VERSION ""

NS_ :

BS_:

BU_: shit BMS

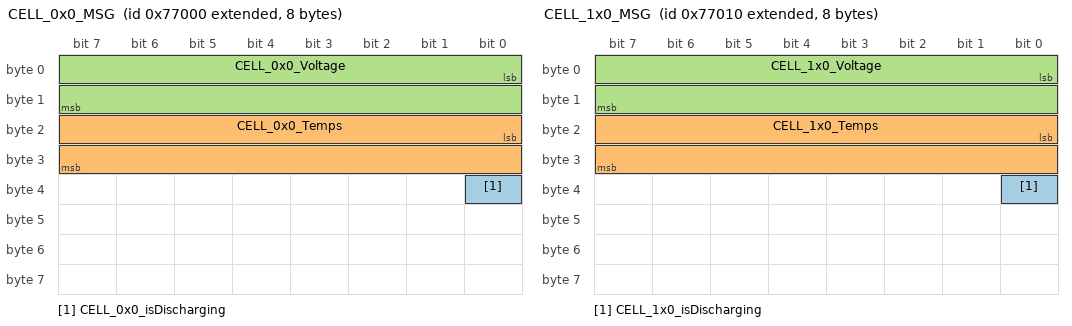
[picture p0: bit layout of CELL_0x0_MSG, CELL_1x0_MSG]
BO_ 2147971072 CELL_0x0_MSG: 8 BMS
 SG_ CELL_0x0_isDischarging : 32|1@1- (1,0) [0|0] "V" Vector__XXX
 SG_ CELL_0x0_Temps : 16|16@1- (1,0) [0|0] "V" Vector__XXX
 SG_ CELL_0x0_Voltage : 0|16@1- (1,0) [0|0] "V" Vector__XXX

BO_ 2147971088 CELL_1x0_MSG: 8 BMS
 SG_ CELL_1x0_isDischarging : 32|1@1- (1,0) [0|0] "V" Vector__XXX
 SG_ CELL_1x0_Temps : 16|16@1- (1,0) [0|0] "V" Vector__XXX
 SG_ CELL_1x0_Voltage : 0|16@1- (1,0) [0|0] "V" Vector__XXX

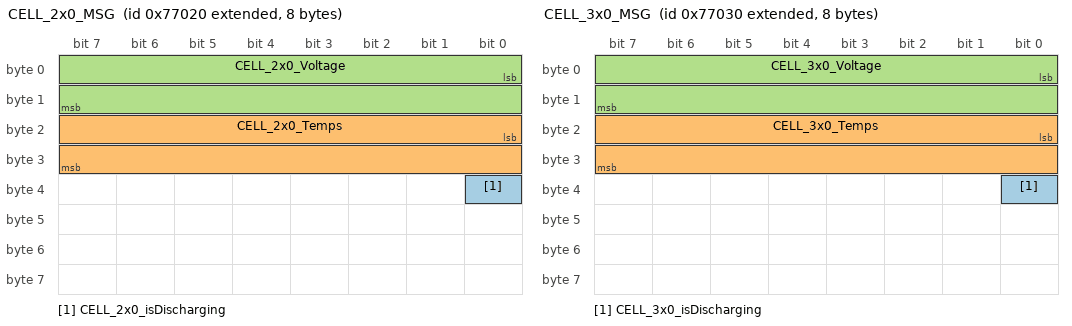
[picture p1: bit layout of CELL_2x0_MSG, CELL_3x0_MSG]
BO_ 2147971104 CELL_2x0_MSG: 8 BMS
 SG_ CELL_2x0_isDischarging : 32|1@1- (1,0) [0|0] "V" Vector__XXX
 SG_ CELL_2x0_Temps : 16|16@1- (1,0) [0|0] "V" Vector__XXX
 SG_ CELL_2x0_Voltage : 0|16@1- (1,0) [0|0] "V" Vector__XXX

BO_ 2147971120 CELL_3x0_MSG: 8 BMS
 SG_ CELL_3x0_isDischarging : 32|1@1- (1,0) [0|0] "V" Vector__XXX
 SG_ CELL_3x0_Temps : 16|16@1- (1,0) [0|0] "V" Vector__XXX
 SG_ CELL_3x0_Voltage : 0|16@1- (1,0) [0|0] "V" Vector__XXX

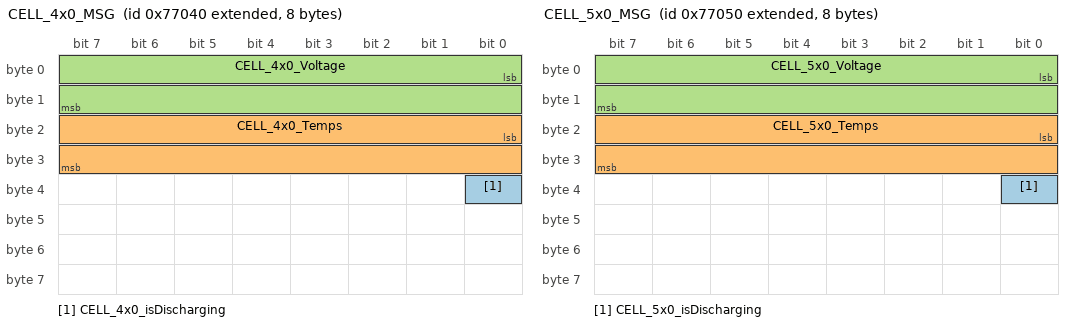
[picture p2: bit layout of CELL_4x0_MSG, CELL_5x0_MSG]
BO_ 2147971136 CELL_4x0_MSG: 8 BMS
 SG_ CELL_4x0_isDischarging : 32|1@1- (1,0) [0|0] "V" Vector__XXX
 SG_ CELL_4x0_Temps : 16|16@1- (1,0) [0|0] "V" Vector__XXX
 SG_ CELL_4x0_Voltage : 0|16@1- (1,0) [0|0] "V" Vector__XXX

BO_ 2147971152 CELL_5x0_MSG: 8 BMS
 SG_ CELL_5x0_isDischarging : 32|1@1- (1,0) [0|0] "V" Vector__XXX
 SG_ CELL_5x0_Temps : 16|16@1- (1,0) [0|0] "V" Vector__XXX
 SG_ CELL_5x0_Voltage : 0|16@1- (1,0) [0|0] "V" Vector__XXX

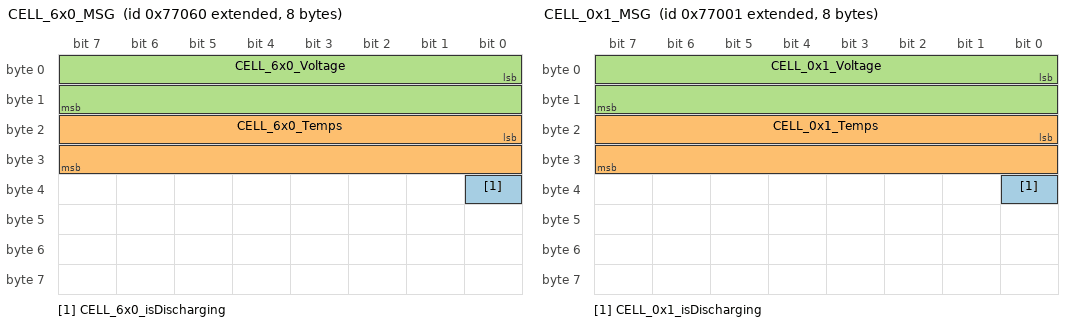
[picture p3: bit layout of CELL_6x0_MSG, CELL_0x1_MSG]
BO_ 2147971168 CELL_6x0_MSG: 8 BMS
 SG_ CELL_6x0_isDischarging : 32|1@1- (1,0) [0|0] "V" Vector__XXX
 SG_ CELL_6x0_Temps : 16|16@1- (1,0) [0|0] "V" Vector__XXX
 SG_ CELL_6x0_Voltage : 0|16@1- (1,0) [0|0] "V" Vector__XXX

BO_ 2147971073 CELL_0x1_MSG: 8 BMS
 SG_ CELL_0x1_isDischarging : 32|1@1- (1,0) [0|0] "V" Vector__XXX
 SG_ CELL_0x1_Temps : 16|16@1- (1,0) [0|0] "V" Vector__XXX
 SG_ CELL_0x1_Voltage : 0|16@1- (1,0) [0|0] "V" Vector__XXX

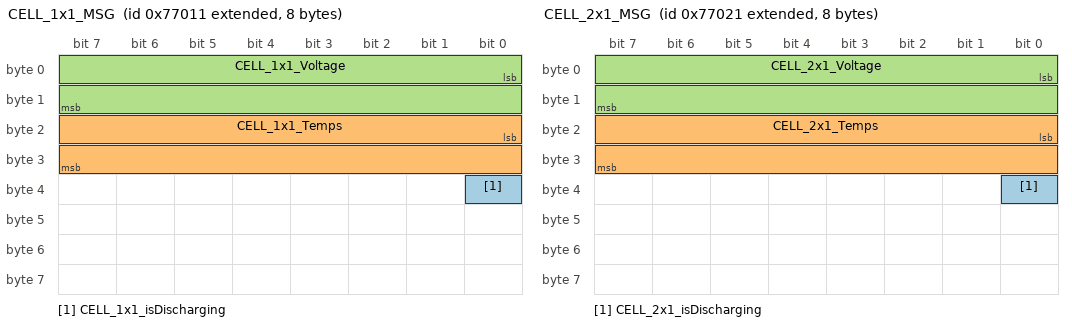
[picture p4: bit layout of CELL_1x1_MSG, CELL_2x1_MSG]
BO_ 2147971089 CELL_1x1_MSG: 8 BMS
 SG_ CELL_1x1_isDischarging : 32|1@1- (1,0) [0|0] "V" Vector__XXX
 SG_ CELL_1x1_Temps : 16|16@1- (1,0) [0|0] "V" Vector__XXX
 SG_ CELL_1x1_Voltage : 0|16@1- (1,0) [0|0] "V" Vector__XXX

BO_ 2147971105 CELL_2x1_MSG: 8 BMS
 SG_ CELL_2x1_isDischarging : 32|1@1- (1,0) [0|0] "V" Vector__XXX
 SG_ CELL_2x1_Temps : 16|16@1- (1,0) [0|0] "V" Vector__XXX
 SG_ CELL_2x1_Voltage : 0|16@1- (1,0) [0|0] "V" Vector__XXX

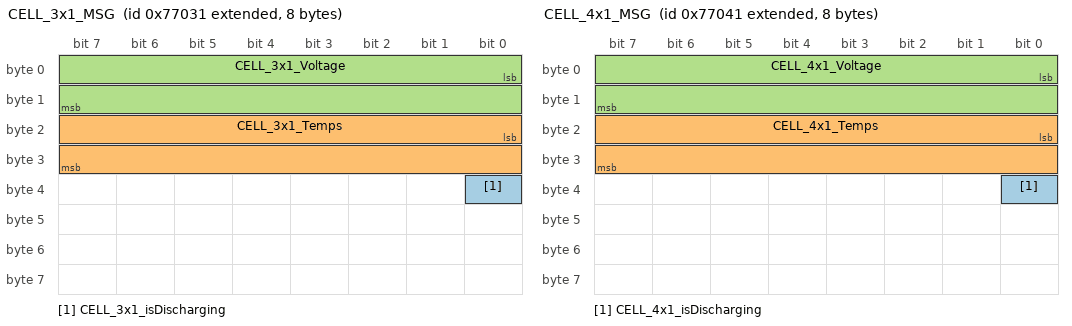
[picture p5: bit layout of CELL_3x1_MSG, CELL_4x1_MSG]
BO_ 2147971121 CELL_3x1_MSG: 8 BMS
 SG_ CELL_3x1_isDischarging : 32|1@1- (1,0) [0|0] "V" Vector__XXX
 SG_ CELL_3x1_Temps : 16|16@1- (1,0) [0|0] "V" Vector__XXX
 SG_ CELL_3x1_Voltage : 0|16@1- (1,0) [0|0] "V" Vector__XXX

BO_ 2147971137 CELL_4x1_MSG: 8 BMS
 SG_ CELL_4x1_isDischarging : 32|1@1- (1,0) [0|0] "V" Vector__XXX
 SG_ CELL_4x1_Temps : 16|16@1- (1,0) [0|0] "V" Vector__XXX
 SG_ CELL_4x1_Voltage : 0|16@1- (1,0) [0|0] "V" Vector__XXX

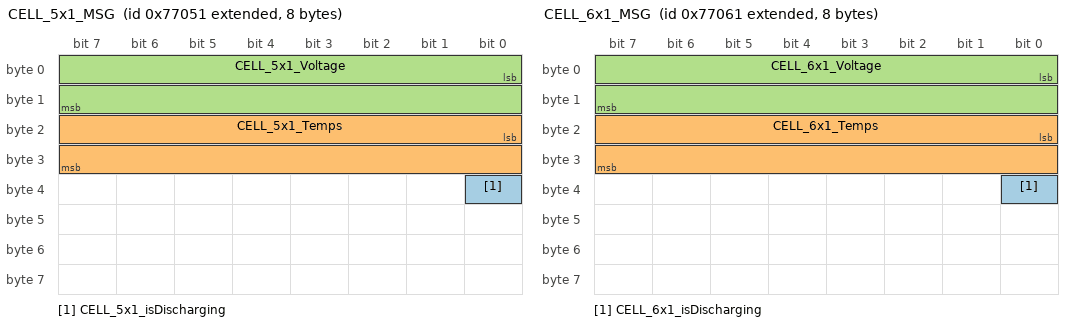
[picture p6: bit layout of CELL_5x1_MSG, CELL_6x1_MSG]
BO_ 2147971153 CELL_5x1_MSG: 8 BMS
 SG_ CELL_5x1_isDischarging : 32|1@1- (1,0) [0|0] "V" Vector__XXX
 SG_ CELL_5x1_Temps : 16|16@1- (1,0) [0|0] "V" Vector__XXX
 SG_ CELL_5x1_Voltage : 0|16@1- (1,0) [0|0] "V" Vector__XXX

BO_ 2147971169 CELL_6x1_MSG: 8 BMS
 SG_ CELL_6x1_isDischarging : 32|1@1- (1,0) [0|0] "V" Vector__XXX
 SG_ CELL_6x1_Temps : 16|16@1- (1,0) [0|0] "V" Vector__XXX
 SG_ CELL_6x1_Voltage : 0|16@1- (1,0) [0|0] "V" Vector__XXX

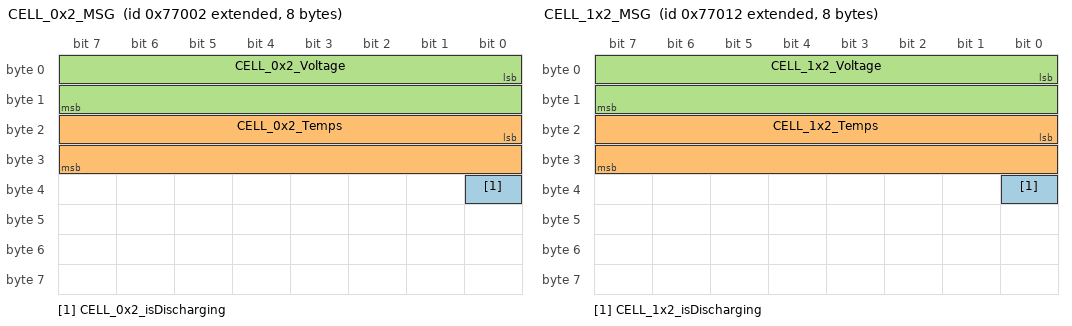
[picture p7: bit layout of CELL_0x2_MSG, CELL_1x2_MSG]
BO_ 2147971074 CELL_0x2_MSG: 8 BMS
 SG_ CELL_0x2_isDischarging : 32|1@1- (1,0) [0|0] "V" Vector__XXX
 SG_ CELL_0x2_Temps : 16|16@1- (1,0) [0|0] "V" Vector__XXX
 SG_ CELL_0x2_Voltage : 0|16@1- (1,0) [0|0] "V" Vector__XXX

BO_ 2147971090 CELL_1x2_MSG: 8 BMS
 SG_ CELL_1x2_isDischarging : 32|1@1- (1,0) [0|0] "V" Vector__XXX
 SG_ CELL_1x2_Temps : 16|16@1- (1,0) [0|0] "V" Vector__XXX
 SG_ CELL_1x2_Voltage : 0|16@1- (1,0) [0|0] "V" Vector__XXX

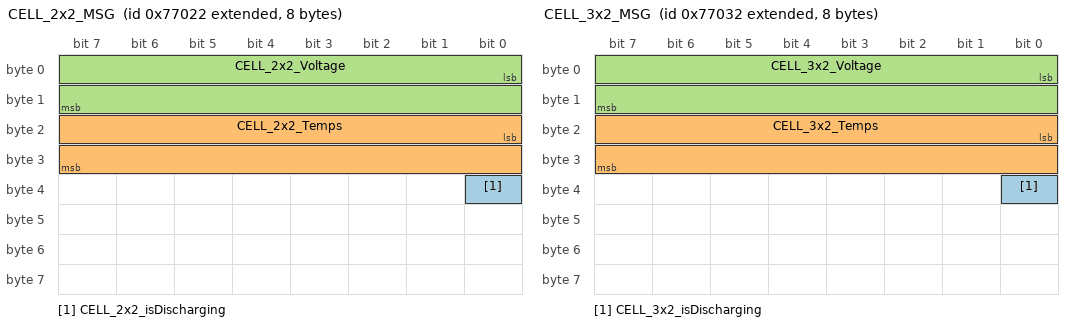
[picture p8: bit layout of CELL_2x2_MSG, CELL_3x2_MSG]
BO_ 2147971106 CELL_2x2_MSG: 8 BMS
 SG_ CELL_2x2_isDischarging : 32|1@1- (1,0) [0|0] "V" Vector__XXX
 SG_ CELL_2x2_Temps : 16|16@1- (1,0) [0|0] "V" Vector__XXX
 SG_ CELL_2x2_Voltage : 0|16@1- (1,0) [0|0] "V" Vector__XXX

BO_ 2147971122 CELL_3x2_MSG: 8 BMS
 SG_ CELL_3x2_isDischarging : 32|1@1- (1,0) [0|0] "V" Vector__XXX
 SG_ CELL_3x2_Temps : 16|16@1- (1,0) [0|0] "V" Vector__XXX
 SG_ CELL_3x2_Voltage : 0|16@1- (1,0) [0|0] "V" Vector__XXX

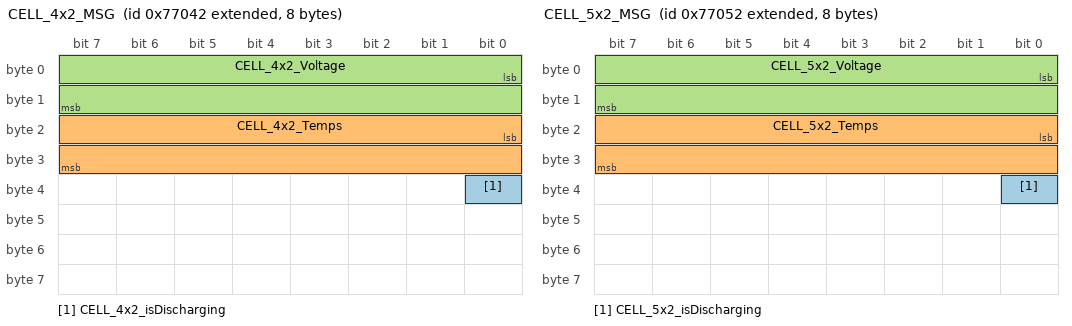
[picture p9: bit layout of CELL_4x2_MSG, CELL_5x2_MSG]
BO_ 2147971138 CELL_4x2_MSG: 8 BMS
 SG_ CELL_4x2_isDischarging : 32|1@1- (1,0) [0|0] "V" Vector__XXX
 SG_ CELL_4x2_Temps : 16|16@1- (1,0) [0|0] "V" Vector__XXX
 SG_ CELL_4x2_Voltage : 0|16@1- (1,0) [0|0] "V" Vector__XXX

BO_ 2147971154 CELL_5x2_MSG: 8 BMS
 SG_ CELL_5x2_isDischarging : 32|1@1- (1,0) [0|0] "V" Vector__XXX
 SG_ CELL_5x2_Temps : 16|16@1- (1,0) [0|0] "V" Vector__XXX
 SG_ CELL_5x2_Voltage : 0|16@1- (1,0) [0|0] "V" Vector__XXX

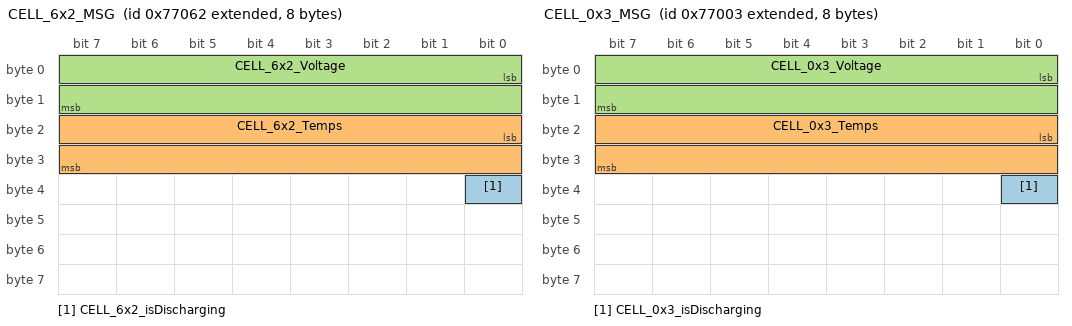
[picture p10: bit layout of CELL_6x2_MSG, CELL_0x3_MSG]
BO_ 2147971170 CELL_6x2_MSG: 8 BMS
 SG_ CELL_6x2_isDischarging : 32|1@1- (1,0) [0|0] "V" Vector__XXX
 SG_ CELL_6x2_Temps : 16|16@1- (1,0) [0|0] "V" Vector__XXX
 SG_ CELL_6x2_Voltage : 0|16@1- (1,0) [0|0] "V" Vector__XXX

BO_ 2147971075 CELL_0x3_MSG: 8 BMS
 SG_ CELL_0x3_isDischarging : 32|1@1- (1,0) [0|0] "V" Vector__XXX
 SG_ CELL_0x3_Temps : 16|16@1- (1,0) [0|0] "V" Vector__XXX
 SG_ CELL_0x3_Voltage : 0|16@1- (1,0) [0|0] "V" Vector__XXX

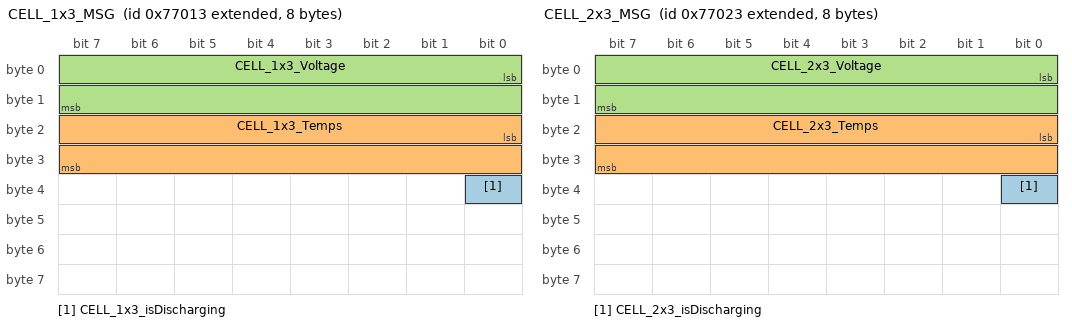
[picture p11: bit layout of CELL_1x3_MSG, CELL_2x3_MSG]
BO_ 2147971091 CELL_1x3_MSG: 8 BMS
 SG_ CELL_1x3_isDischarging : 32|1@1- (1,0) [0|0] "V" Vector__XXX
 SG_ CELL_1x3_Temps : 16|16@1- (1,0) [0|0] "V" Vector__XXX
 SG_ CELL_1x3_Voltage : 0|16@1- (1,0) [0|0] "V" Vector__XXX

BO_ 2147971107 CELL_2x3_MSG: 8 BMS
 SG_ CELL_2x3_isDischarging : 32|1@1- (1,0) [0|0] "V" Vector__XXX
 SG_ CELL_2x3_Temps : 16|16@1- (1,0) [0|0] "V" Vector__XXX
 SG_ CELL_2x3_Voltage : 0|16@1- (1,0) [0|0] "V" Vector__XXX

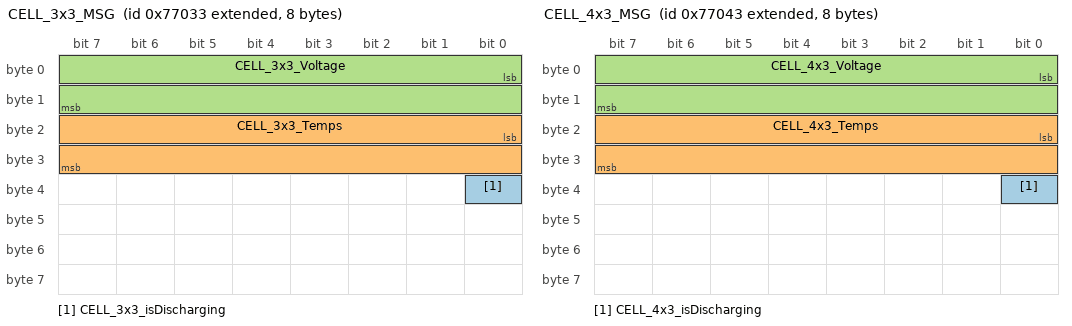
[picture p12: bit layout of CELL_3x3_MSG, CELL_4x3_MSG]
BO_ 2147971123 CELL_3x3_MSG: 8 BMS
 SG_ CELL_3x3_isDischarging : 32|1@1- (1,0) [0|0] "V" Vector__XXX
 SG_ CELL_3x3_Temps : 16|16@1- (1,0) [0|0] "V" Vector__XXX
 SG_ CELL_3x3_Voltage : 0|16@1- (1,0) [0|0] "V" Vector__XXX

BO_ 2147971139 CELL_4x3_MSG: 8 BMS
 SG_ CELL_4x3_isDischarging : 32|1@1- (1,0) [0|0] "V" Vector__XXX
 SG_ CELL_4x3_Temps : 16|16@1- (1,0) [0|0] "V" Vector__XXX
 SG_ CELL_4x3_Voltage : 0|16@1- (1,0) [0|0] "V" Vector__XXX

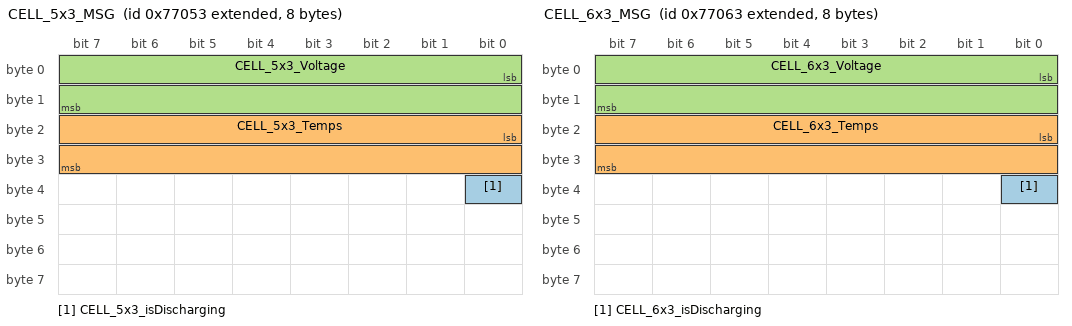
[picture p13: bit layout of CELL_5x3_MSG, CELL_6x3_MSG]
BO_ 2147971155 CELL_5x3_MSG: 8 BMS
 SG_ CELL_5x3_isDischarging : 32|1@1- (1,0) [0|0] "V" Vector__XXX
 SG_ CELL_5x3_Temps : 16|16@1- (1,0) [0|0] "V" Vector__XXX
 SG_ CELL_5x3_Voltage : 0|16@1- (1,0) [0|0] "V" Vector__XXX

BO_ 2147971171 CELL_6x3_MSG: 8 BMS
 SG_ CELL_6x3_isDischarging : 32|1@1- (1,0) [0|0] "V" Vector__XXX
 SG_ CELL_6x3_Temps : 16|16@1- (1,0) [0|0] "V" Vector__XXX
 SG_ CELL_6x3_Voltage : 0|16@1- (1,0) [0|0] "V" Vector__XXX

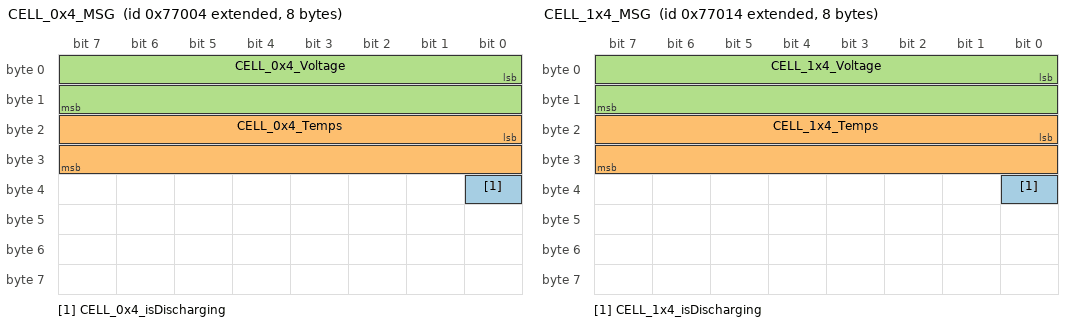
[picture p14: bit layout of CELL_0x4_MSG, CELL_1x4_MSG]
BO_ 2147971076 CELL_0x4_MSG: 8 BMS
 SG_ CELL_0x4_isDischarging : 32|1@1- (1,0) [0|0] "V" Vector__XXX
 SG_ CELL_0x4_Temps : 16|16@1- (1,0) [0|0] "V" Vector__XXX
 SG_ CELL_0x4_Voltage : 0|16@1- (1,0) [0|0] "V" Vector__XXX

BO_ 2147971092 CELL_1x4_MSG: 8 BMS
 SG_ CELL_1x4_isDischarging : 32|1@1- (1,0) [0|0] "V" Vector__XXX
 SG_ CELL_1x4_Temps : 16|16@1- (1,0) [0|0] "V" Vector__XXX
 SG_ CELL_1x4_Voltage : 0|16@1- (1,0) [0|0] "V" Vector__XXX

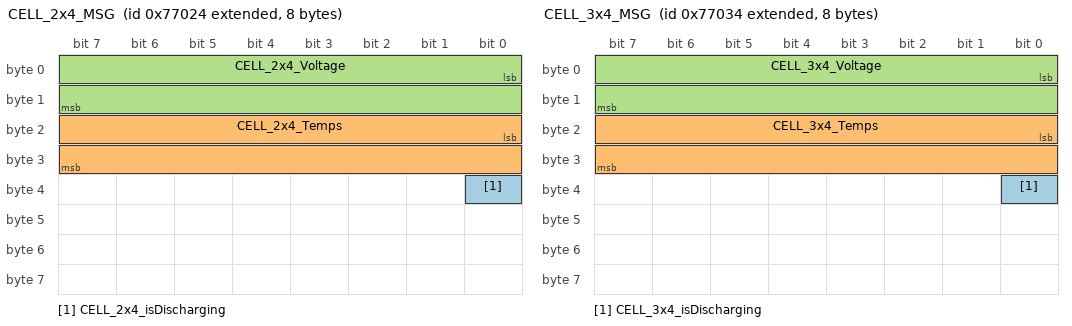
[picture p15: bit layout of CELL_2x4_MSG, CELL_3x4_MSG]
BO_ 2147971108 CELL_2x4_MSG: 8 BMS
 SG_ CELL_2x4_isDischarging : 32|1@1- (1,0) [0|0] "V" Vector__XXX
 SG_ CELL_2x4_Temps : 16|16@1- (1,0) [0|0] "V" Vector__XXX
 SG_ CELL_2x4_Voltage : 0|16@1- (1,0) [0|0] "V" Vector__XXX

BO_ 2147971124 CELL_3x4_MSG: 8 BMS
 SG_ CELL_3x4_isDischarging : 32|1@1- (1,0) [0|0] "V" Vector__XXX
 SG_ CELL_3x4_Temps : 16|16@1- (1,0) [0|0] "V" Vector__XXX
 SG_ CELL_3x4_Voltage : 0|16@1- (1,0) [0|0] "V" Vector__XXX

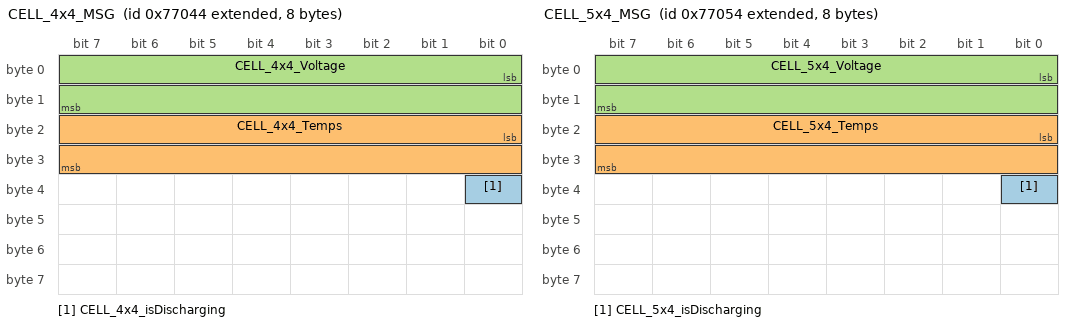
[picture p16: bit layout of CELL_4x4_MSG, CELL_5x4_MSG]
BO_ 2147971140 CELL_4x4_MSG: 8 BMS
 SG_ CELL_4x4_isDischarging : 32|1@1- (1,0) [0|0] "V" Vector__XXX
 SG_ CELL_4x4_Temps : 16|16@1- (1,0) [0|0] "V" Vector__XXX
 SG_ CELL_4x4_Voltage : 0|16@1- (1,0) [0|0] "V" Vector__XXX

BO_ 2147971156 CELL_5x4_MSG: 8 BMS
 SG_ CELL_5x4_isDischarging : 32|1@1- (1,0) [0|0] "V" Vector__XXX
 SG_ CELL_5x4_Temps : 16|16@1- (1,0) [0|0] "V" Vector__XXX
 SG_ CELL_5x4_Voltage : 0|16@1- (1,0) [0|0] "V" Vector__XXX

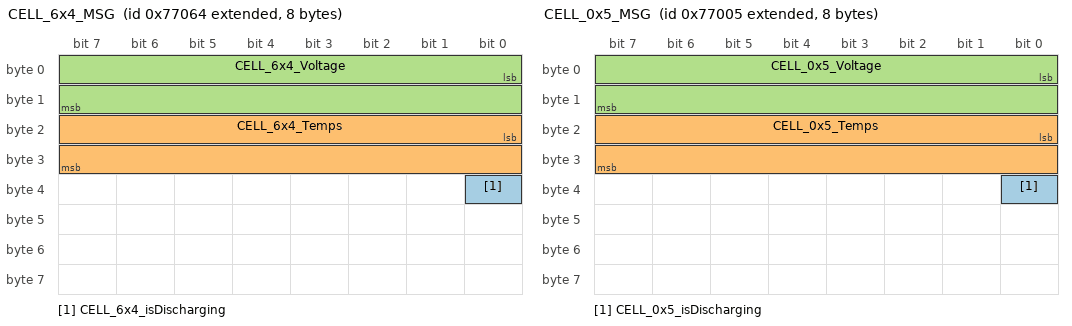
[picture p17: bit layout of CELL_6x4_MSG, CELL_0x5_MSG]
BO_ 2147971172 CELL_6x4_MSG: 8 BMS
 SG_ CELL_6x4_isDischarging : 32|1@1- (1,0) [0|0] "V" Vector__XXX
 SG_ CELL_6x4_Temps : 16|16@1- (1,0) [0|0] "V" Vector__XXX
 SG_ CELL_6x4_Voltage : 0|16@1- (1,0) [0|0] "V" Vector__XXX

BO_ 2147971077 CELL_0x5_MSG: 8 BMS
 SG_ CELL_0x5_isDischarging : 32|1@1- (1,0) [0|0] "V" Vector__XXX
 SG_ CELL_0x5_Temps : 16|16@1- (1,0) [0|0] "V" Vector__XXX
 SG_ CELL_0x5_Voltage : 0|16@1- (1,0) [0|0] "V" Vector__XXX

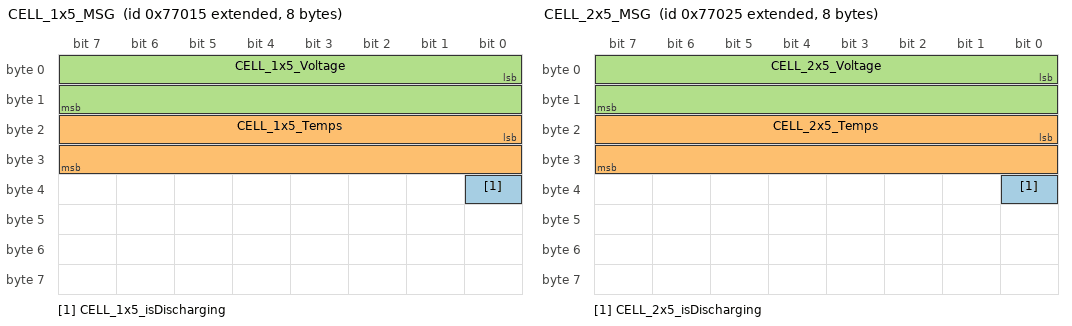
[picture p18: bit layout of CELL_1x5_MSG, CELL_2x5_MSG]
BO_ 2147971093 CELL_1x5_MSG: 8 BMS
 SG_ CELL_1x5_isDischarging : 32|1@1- (1,0) [0|0] "V" Vector__XXX
 SG_ CELL_1x5_Temps : 16|16@1- (1,0) [0|0] "V" Vector__XXX
 SG_ CELL_1x5_Voltage : 0|16@1- (1,0) [0|0] "V" Vector__XXX

BO_ 2147971109 CELL_2x5_MSG: 8 BMS
 SG_ CELL_2x5_isDischarging : 32|1@1- (1,0) [0|0] "V" Vector__XXX
 SG_ CELL_2x5_Temps : 16|16@1- (1,0) [0|0] "V" Vector__XXX
 SG_ CELL_2x5_Voltage : 0|16@1- (1,0) [0|0] "V" Vector__XXX

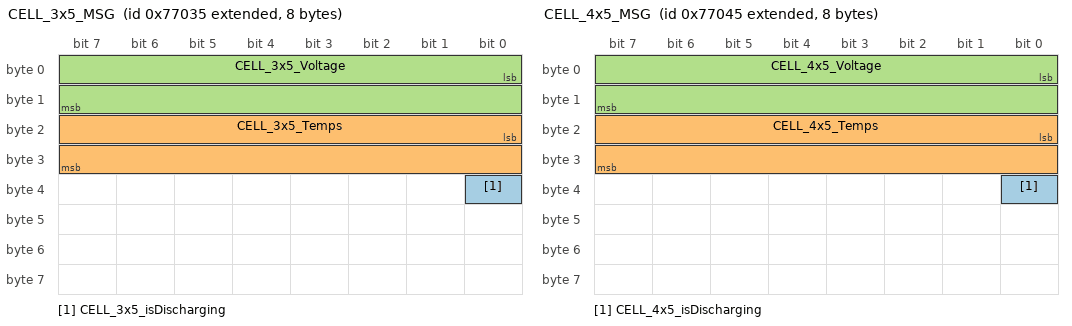
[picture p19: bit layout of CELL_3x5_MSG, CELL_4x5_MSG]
BO_ 2147971125 CELL_3x5_MSG: 8 BMS
 SG_ CELL_3x5_isDischarging : 32|1@1- (1,0) [0|0] "V" Vector__XXX
 SG_ CELL_3x5_Temps : 16|16@1- (1,0) [0|0] "V" Vector__XXX
 SG_ CELL_3x5_Voltage : 0|16@1- (1,0) [0|0] "V" Vector__XXX

BO_ 2147971141 CELL_4x5_MSG: 8 BMS
 SG_ CELL_4x5_isDischarging : 32|1@1- (1,0) [0|0] "V" Vector__XXX
 SG_ CELL_4x5_Temps : 16|16@1- (1,0) [0|0] "V" Vector__XXX
 SG_ CELL_4x5_Voltage : 0|16@1- (1,0) [0|0] "V" Vector__XXX

BO_ 2147971157 CELL_5x5_MSG: 8 BMS
 SG_ CELL_5x5_isDischarging : 32|1@1- (1,0) [0|0] "V" Vector__XXX
 SG_ CELL_5x5_Temps : 16|16@1- (1,0) [0|0] "V" Vector__XXX
 SG_ CELL_5x5_Voltage : 0|16@1- (1,0) [0|0] "V" Vector__XXX

BO_ 2147971173 CELL_6x5_MSG: 8 BMS
 SG_ CELL_6x5_isDischarging : 32|1@1- (1,0) [0|0] "V" Vector__XXX
 SG_ CELL_6x5_Temps : 16|16@1- (1,0) [0|0] "V" Vector__XXX
 SG_ CELL_6x5_Voltage : 0|16@1- (1,0) [0|0] "V" Vector__XXX

BO_ 2147971078 CELL_0x6_MSG: 8 BMS
 SG_ CELL_0x6_isDischarging : 32|1@1- (1,0) [0|0] "V" Vector__XXX
 SG_ CELL_0x6_Temps : 16|16@1- (1,0) [0|0] "V" Vector__XXX
 SG_ CELL_0x6_Voltage : 0|16@1- (1,0) [0|0] "V" Vector__XXX

BO_ 2147971094 CELL_1x6_MSG: 8 BMS
 SG_ CELL_1x6_isDischarging : 32|1@1- (1,0) [0|0] "V" Vector__XXX
 SG_ CELL_1x6_Temps : 16|16@1- (1,0) [0|0] "V" Vector__XXX
 SG_ CELL_1x6_Voltage : 0|16@1- (1,0) [0|0] "V" Vector__XXX

BO_ 2147971110 CELL_2x6_MSG: 8 BMS
 SG_ CELL_2x6_isDischarging : 32|1@1- (1,0) [0|0] "V" Vector__XXX
 SG_ CELL_2x6_Temps : 16|16@1- (1,0) [0|0] "V" Vector__XXX
 SG_ CELL_2x6_Voltage : 0|16@1- (1,0) [0|0] "V" Vector__XXX

BO_ 2147971126 CELL_3x6_MSG: 8 BMS
 SG_ CELL_3x6_isDischarging : 32|1@1- (1,0) [0|0] "V" Vector__XXX
 SG_ CELL_3x6_Temps : 16|16@1- (1,0) [0|0] "V" Vector__XXX
 SG_ CELL_3x6_Voltage : 0|16@1- (1,0) [0|0] "V" Vector__XXX

BO_ 2147971142 CELL_4x6_MSG: 8 BMS
 SG_ CELL_4x6_isDischarging : 32|1@1- (1,0) [0|0] "V" Vector__XXX
 SG_ CELL_4x6_Temps : 16|16@1- (1,0) [0|0] "V" Vector__XXX
 SG_ CELL_4x6_Voltage : 0|16@1- (1,0) [0|0] "V" Vector__XXX

BO_ 2147971158 CELL_5x6_MSG: 8 BMS
 SG_ CELL_5x6_isDischarging : 32|1@1- (1,0) [0|0] "V" Vector__XXX
 SG_ CELL_5x6_Temps : 16|16@1- (1,0) [0|0] "V" Vector__XXX
 SG_ CELL_5x6_Voltage : 0|16@1- (1,0) [0|0] "V" Vector__XXX

BO_ 2147971174 CELL_6x6_MSG: 8 BMS
 SG_ CELL_6x6_isDischarging : 32|1@1- (1,0) [0|0] "V" Vector__XXX
 SG_ CELL_6x6_Temps : 16|16@1- (1,0) [0|0] "V" Vector__XXX
 SG_ CELL_6x6_Voltage : 0|16@1- (1,0) [0|0] "V" Vector__XXX

BO_ 2147971079 CELL_0x7_MSG: 8 BMS
 SG_ CELL_0x7_isDischarging : 32|1@1- (1,0) [0|0] "V" Vector__XXX
 SG_ CELL_0x7_Temps : 16|16@1- (1,0) [0|0] "V" Vector__XXX
 SG_ CELL_0x7_Voltage : 0|16@1- (1,0) [0|0] "V" Vector__XXX

BO_ 2147971095 CELL_1x7_MSG: 8 BMS
 SG_ CELL_1x7_isDischarging : 32|1@1- (1,0) [0|0] "V" Vector__XXX
 SG_ CELL_1x7_Temps : 16|16@1- (1,0) [0|0] "V" Vector__XXX
 SG_ CELL_1x7_Voltage : 0|16@1- (1,0) [0|0] "V" Vector__XXX

BO_ 2147971111 CELL_2x7_MSG: 8 BMS
 SG_ CELL_2x7_isDischarging : 32|1@1- (1,0) [0|0] "V" Vector__XXX
 SG_ CELL_2x7_Temps : 16|16@1- (1,0) [0|0] "V" Vector__XXX
 SG_ CELL_2x7_Voltage : 0|16@1- (1,0) [0|0] "V" Vector__XXX

BO_ 2147971127 CELL_3x7_MSG: 8 BMS
 SG_ CELL_3x7_isDischarging : 32|1@1- (1,0) [0|0] "V" Vector__XXX
 SG_ CELL_3x7_Temps : 16|16@1- (1,0) [0|0] "V" Vector__XXX
 SG_ CELL_3x7_Voltage : 0|16@1- (1,0) [0|0] "V" Vector__XXX

BO_ 2147971143 CELL_4x7_MSG: 8 BMS
 SG_ CELL_4x7_isDischarging : 32|1@1- (1,0) [0|0] "V" Vector__XXX
 SG_ CELL_4x7_Temps : 16|16@1- (1,0) [0|0] "V" Vector__XXX
 SG_ CELL_4x7_Voltage : 0|16@1- (1,0) [0|0] "V" Vector__XXX

BO_ 2147971159 CELL_5x7_MSG: 8 BMS
 SG_ CELL_5x7_isDischarging : 32|1@1- (1,0) [0|0] "V" Vector__XXX
 SG_ CELL_5x7_Temps : 16|16@1- (1,0) [0|0] "V" Vector__XXX
 SG_ CELL_5x7_Voltage : 0|16@1- (1,0) [0|0] "V" Vector__XXX

BO_ 2147971175 CELL_6x7_MSG: 8 BMS
 SG_ CELL_6x7_isDischarging : 32|1@1- (1,0) [0|0] "V" Vector__XXX
 SG_ CELL_6x7_Temps : 16|16@1- (1,0) [0|0] "V" Vector__XXX
 SG_ CELL_6x7_Voltage : 0|16@1- (1,0) [0|0] "V" Vector__XXX

BO_ 2147971080 CELL_0x8_MSG: 8 BMS
 SG_ CELL_0x8_isDischarging : 32|1@1- (1,0) [0|0] "V" Vector__XXX
 SG_ CELL_0x8_Temps : 16|16@1- (1,0) [0|0] "V" Vector__XXX
 SG_ CELL_0x8_Voltage : 0|16@1- (1,0) [0|0] "V" Vector__XXX

BO_ 2147971096 CELL_1x8_MSG: 8 BMS
 SG_ CELL_1x8_isDischarging : 32|1@1- (1,0) [0|0] "V" Vector__XXX
 SG_ CELL_1x8_Temps : 16|16@1- (1,0) [0|0] "V" Vector__XXX
 SG_ CELL_1x8_Voltage : 0|16@1- (1,0) [0|0] "V" Vector__XXX

BO_ 2147971112 CELL_2x8_MSG: 8 BMS
 SG_ CELL_2x8_isDischarging : 32|1@1- (1,0) [0|0] "V" Vector__XXX
 SG_ CELL_2x8_Temps : 16|16@1- (1,0) [0|0] "V" Vector__XXX
 SG_ CELL_2x8_Voltage : 0|16@1- (1,0) [0|0] "V" Vector__XXX

BO_ 2147971128 CELL_3x8_MSG: 8 BMS
 SG_ CELL_3x8_isDischarging : 32|1@1- (1,0) [0|0] "V" Vector__XXX
 SG_ CELL_3x8_Temps : 16|16@1- (1,0) [0|0] "V" Vector__XXX
 SG_ CELL_3x8_Voltage : 0|16@1- (1,0) [0|0] "V" Vector__XXX

BO_ 2147971144 CELL_4x8_MSG: 8 BMS
 SG_ CELL_4x8_isDischarging : 32|1@1- (1,0) [0|0] "V" Vector__XXX
 SG_ CELL_4x8_Temps : 16|16@1- (1,0) [0|0] "V" Vector__XXX
 SG_ CELL_4x8_Voltage : 0|16@1- (1,0) [0|0] "V" Vector__XXX

BO_ 2147971160 CELL_5x8_MSG: 8 BMS
 SG_ CELL_5x8_isDischarging : 32|1@1- (1,0) [0|0] "V" Vector__XXX
 SG_ CELL_5x8_Temps : 16|16@1- (1,0) [0|0] "V" Vector__XXX
 SG_ CELL_5x8_Voltage : 0|16@1- (1,0) [0|0] "V" Vector__XXX

BO_ 2147971176 CELL_6x8_MSG: 8 BMS
 SG_ CELL_6x8_isDischarging : 32|1@1- (1,0) [0|0] "V" Vector__XXX
 SG_ CELL_6x8_Temps : 16|16@1- (1,0) [0|0] "V" Vector__XXX
 SG_ CELL_6x8_Voltage : 0|16@1- (1,0) [0|0] "V" Vector__XXX

BO_ 2147971081 CELL_0x9_MSG: 8 BMS
 SG_ CELL_0x9_isDischarging : 32|1@1- (1,0) [0|0] "V" Vector__XXX
 SG_ CELL_0x9_Temps : 16|16@1- (1,0) [0|0] "V" Vector__XXX
 SG_ CELL_0x9_Voltage : 0|16@1- (1,0) [0|0] "V" Vector__XXX

BO_ 2147971097 CELL_1x9_MSG: 8 BMS
 SG_ CELL_1x9_isDischarging : 32|1@1- (1,0) [0|0] "V" Vector__XXX
 SG_ CELL_1x9_Temps : 16|16@1- (1,0) [0|0] "V" Vector__XXX
 SG_ CELL_1x9_Voltage : 0|16@1- (1,0) [0|0] "V" Vector__XXX

BO_ 2147971113 CELL_2x9_MSG: 8 BMS
 SG_ CELL_2x9_isDischarging : 32|1@1- (1,0) [0|0] "V" Vector__XXX
 SG_ CELL_2x9_Temps : 16|16@1- (1,0) [0|0] "V" Vector__XXX
 SG_ CELL_2x9_Voltage : 0|16@1- (1,0) [0|0] "V" Vector__XXX

BO_ 2147971129 CELL_3x9_MSG: 8 BMS
 SG_ CELL_3x9_isDischarging : 32|1@1- (1,0) [0|0] "V" Vector__XXX
 SG_ CELL_3x9_Temps : 16|16@1- (1,0) [0|0] "V" Vector__XXX
 SG_ CELL_3x9_Voltage : 0|16@1- (1,0) [0|0] "V" Vector__XXX

BO_ 2147971145 CELL_4x9_MSG: 8 BMS
 SG_ CELL_4x9_isDischarging : 32|1@1- (1,0) [0|0] "V" Vector__XXX
 SG_ CELL_4x9_Temps : 16|16@1- (1,0) [0|0] "V" Vector__XXX
 SG_ CELL_4x9_Voltage : 0|16@1- (1,0) [0|0] "V" Vector__XXX

BO_ 2147971161 CELL_5x9_MSG: 8 BMS
 SG_ CELL_5x9_isDischarging : 32|1@1- (1,0) [0|0] "V" Vector__XXX
 SG_ CELL_5x9_Temps : 16|16@1- (1,0) [0|0] "V" Vector__XXX
 SG_ CELL_5x9_Voltage : 0|16@1- (1,0) [0|0] "V" Vector__XXX

BO_ 2147971177 CELL_6x9_MSG: 8 BMS
 SG_ CELL_6x9_isDischarging : 32|1@1- (1,0) [0|0] "V" Vector__XXX
 SG_ CELL_6x9_Temps : 16|16@1- (1,0) [0|0] "V" Vector__XXX
 SG_ CELL_6x9_Voltage : 0|16@1- (1,0) [0|0] "V" Vector__XXX

BO_ 2147971082 CELL_0x10_MSG: 8 BMS
 SG_ CELL_0x10_isDischarging : 32|1@1- (1,0) [0|0] "V" Vector__XXX
 SG_ CELL_0x10_Temps : 16|16@1- (1,0) [0|0] "V" Vector__XXX
 SG_ CELL_0x10_Voltage : 0|16@1- (1,0) [0|0] "V" Vector__XXX

BO_ 2147971098 CELL_1x10_MSG: 8 BMS
 SG_ CELL_1x10_isDischarging : 32|1@1- (1,0) [0|0] "V" Vector__XXX
 SG_ CELL_1x10_Temps : 16|16@1- (1,0) [0|0] "V" Vector__XXX
 SG_ CELL_1x10_Voltage : 0|16@1- (1,0) [0|0] "V" Vector__XXX

BO_ 2147971114 CELL_2x10_MSG: 8 BMS
 SG_ CELL_2x10_isDischarging : 32|1@1- (1,0) [0|0] "V" Vector__XXX
 SG_ CELL_2x10_Temps : 16|16@1- (1,0) [0|0] "V" Vector__XXX
 SG_ CELL_2x10_Voltage : 0|16@1- (1,0) [0|0] "V" Vector__XXX

BO_ 2147971130 CELL_3x10_MSG: 8 BMS
 SG_ CELL_3x10_isDischarging : 32|1@1- (1,0) [0|0] "V" Vector__XXX
 SG_ CELL_3x10_Temps : 16|16@1- (1,0) [0|0] "V" Vector__XXX
 SG_ CELL_3x10_Voltage : 0|16@1- (1,0) [0|0] "V" Vector__XXX

BO_ 2147971146 CELL_4x10_MSG: 8 BMS
 SG_ CELL_4x10_isDischarging : 32|1@1- (1,0) [0|0] "V" Vector__XXX
 SG_ CELL_4x10_Temps : 16|16@1- (1,0) [0|0] "V" Vector__XXX
 SG_ CELL_4x10_Voltage : 0|16@1- (1,0) [0|0] "V" Vector__XXX

BO_ 2147971162 CELL_5x10_MSG: 8 BMS
 SG_ CELL_5x10_isDischarging : 32|1@1- (1,0) [0|0] "V" Vector__XXX
 SG_ CELL_5x10_Temps : 16|16@1- (1,0) [0|0] "V" Vector__XXX
 SG_ CELL_5x10_Voltage : 0|16@1- (1,0) [0|0] "V" Vector__XXX

BO_ 2147971178 CELL_6x10_MSG: 8 BMS
 SG_ CELL_6x10_isDischarging : 32|1@1- (1,0) [0|0] "V" Vector__XXX
 SG_ CELL_6x10_Temps : 16|16@1- (1,0) [0|0] "V" Vector__XXX
 SG_ CELL_6x10_Voltage : 0|16@1- (1,0) [0|0] "V" Vector__XXX

BO_ 2147971083 CELL_0x11_MSG: 8 BMS
 SG_ CELL_0x11_isDischarging : 32|1@1- (1,0) [0|0] "V" Vector__XXX
 SG_ CELL_0x11_Temps : 16|16@1- (1,0) [0|0] "V" Vector__XXX
 SG_ CELL_0x11_Voltage : 0|16@1- (1,0) [0|0] "V" Vector__XXX

BO_ 2147971099 CELL_1x11_MSG: 8 BMS
 SG_ CELL_1x11_isDischarging : 32|1@1- (1,0) [0|0] "V" Vector__XXX
 SG_ CELL_1x11_Temps : 16|16@1- (1,0) [0|0] "V" Vector__XXX
 SG_ CELL_1x11_Voltage : 0|16@1- (1,0) [0|0] "V" Vector__XXX

BO_ 2147971115 CELL_2x11_MSG: 8 BMS
 SG_ CELL_2x11_isDischarging : 32|1@1- (1,0) [0|0] "V" Vector__XXX
 SG_ CELL_2x11_Temps : 16|16@1- (1,0) [0|0] "V" Vector__XXX
 SG_ CELL_2x11_Voltage : 0|16@1- (1,0) [0|0] "V" Vector__XXX

BO_ 2147971131 CELL_3x11_MSG: 8 BMS
 SG_ CELL_3x11_isDischarging : 32|1@1- (1,0) [0|0] "V" Vector__XXX
 SG_ CELL_3x11_Temps : 16|16@1- (1,0) [0|0] "V" Vector__XXX
 SG_ CELL_3x11_Voltage : 0|16@1- (1,0) [0|0] "V" Vector__XXX

BO_ 2147971147 CELL_4x11_MSG: 8 BMS
 SG_ CELL_4x11_isDischarging : 32|1@1- (1,0) [0|0] "V" Vector__XXX
 SG_ CELL_4x11_Temps : 16|16@1- (1,0) [0|0] "V" Vector__XXX
 SG_ CELL_4x11_Voltage : 0|16@1- (1,0) [0|0] "V" Vector__XXX

BO_ 2147971163 CELL_5x11_MSG: 8 BMS
 SG_ CELL_5x11_isDischarging : 32|1@1- (1,0) [0|0] "V" Vector__XXX
 SG_ CELL_5x11_Temps : 16|16@1- (1,0) [0|0] "V" Vector__XXX
 SG_ CELL_5x11_Voltage : 0|16@1- (1,0) [0|0] "V" Vector__XXX

BO_ 2147971179 CELL_6x11_MSG: 8 BMS
 SG_ CELL_6x11_isDischarging : 32|1@1- (1,0) [0|0] "V" Vector__XXX
 SG_ CELL_6x11_Temps : 16|16@1- (1,0) [0|0] "V" Vector__XXX
 SG_ CELL_6x11_Voltage : 0|16@1- (1,0) [0|0] "V" Vector__XXX

BO_ 2147971084 CELL_0x12_MSG: 8 BMS
 SG_ CELL_0x12_isDischarging : 32|1@1- (1,0) [0|0] "V" Vector__XXX
 SG_ CELL_0x12_Temps : 16|16@1- (1,0) [0|0] "V" Vector__XXX
 SG_ CELL_0x12_Voltage : 0|16@1- (1,0) [0|0] "V" Vector__XXX

BO_ 2147971100 CELL_1x12_MSG: 8 BMS
 SG_ CELL_1x12_isDischarging : 32|1@1- (1,0) [0|0] "V" Vector__XXX
 SG_ CELL_1x12_Temps : 16|16@1- (1,0) [0|0] "V" Vector__XXX
 SG_ CELL_1x12_Voltage : 0|16@1- (1,0) [0|0] "V" Vector__XXX

BO_ 2147971116 CELL_2x12_MSG: 8 BMS
 SG_ CELL_2x12_isDischarging : 32|1@1- (1,0) [0|0] "V" Vector__XXX
 SG_ CELL_2x12_Temps : 16|16@1- (1,0) [0|0] "V" Vector__XXX
 SG_ CELL_2x12_Voltage : 0|16@1- (1,0) [0|0] "V" Vector__XXX

BO_ 2147971132 CELL_3x12_MSG: 8 BMS
 SG_ CELL_3x12_isDischarging : 32|1@1- (1,0) [0|0] "V" Vector__XXX
 SG_ CELL_3x12_Temps : 16|16@1- (1,0) [0|0] "V" Vector__XXX
 SG_ CELL_3x12_Voltage : 0|16@1- (1,0) [0|0] "V" Vector__XXX

BO_ 2147971148 CELL_4x12_MSG: 8 BMS
 SG_ CELL_4x12_isDischarging : 32|1@1- (1,0) [0|0] "V" Vector__XXX
 SG_ CELL_4x12_Temps : 16|16@1- (1,0) [0|0] "V" Vector__XXX
 SG_ CELL_4x12_Voltage : 0|16@1- (1,0) [0|0] "V" Vector__XXX

BO_ 2147971164 CELL_5x12_MSG: 8 BMS
 SG_ CELL_5x12_isDischarging : 32|1@1- (1,0) [0|0] "V" Vector__XXX
 SG_ CELL_5x12_Temps : 16|16@1- (1,0) [0|0] "V" Vector__XXX
 SG_ CELL_5x12_Voltage : 0|16@1- (1,0) [0|0] "V" Vector__XXX

BO_ 2147971180 CELL_6x12_MSG: 8 BMS
 SG_ CELL_6x12_isDischarging : 32|1@1- (1,0) [0|0] "V" Vector__XXX
 SG_ CELL_6x12_Temps : 16|16@1- (1,0) [0|0] "V" Vector__XXX
 SG_ CELL_6x12_Voltage : 0|16@1- (1,0) [0|0] "V" Vector__XXX

BO_ 2147971085 CELL_0x13_MSG: 8 BMS
 SG_ CELL_0x13_isDischarging : 32|1@1- (1,0) [0|0] "V" Vector__XXX
 SG_ CELL_0x13_Temps : 16|16@1- (1,0) [0|0] "V" Vector__XXX
 SG_ CELL_0x13_Voltage : 0|16@1- (1,0) [0|0] "V" Vector__XXX

BO_ 2147971101 CELL_1x13_MSG: 8 BMS
 SG_ CELL_1x13_isDischarging : 32|1@1- (1,0) [0|0] "V" Vector__XXX
 SG_ CELL_1x13_Temps : 16|16@1- (1,0) [0|0] "V" Vector__XXX
 SG_ CELL_1x13_Voltage : 0|16@1- (1,0) [0|0] "V" Vector__XXX

BO_ 2147971117 CELL_2x13_MSG: 8 BMS
 SG_ CELL_2x13_isDischarging : 32|1@1- (1,0) [0|0] "V" Vector__XXX
 SG_ CELL_2x13_Temps : 16|16@1- (1,0) [0|0] "V" Vector__XXX
 SG_ CELL_2x13_Voltage : 0|16@1- (1,0) [0|0] "V" Vector__XXX

BO_ 2147971133 CELL_3x13_MSG: 8 BMS
 SG_ CELL_3x13_isDischarging : 32|1@1- (1,0) [0|0] "V" Vector__XXX
 SG_ CELL_3x13_Temps : 16|16@1- (1,0) [0|0] "V" Vector__XXX
 SG_ CELL_3x13_Voltage : 0|16@1- (1,0) [0|0] "V" Vector__XXX

BO_ 2147971149 CELL_4x13_MSG: 8 BMS
 SG_ CELL_4x13_isDischarging : 32|1@1- (1,0) [0|0] "V" Vector__XXX
 SG_ CELL_4x13_Temps : 16|16@1- (1,0) [0|0] "V" Vector__XXX
 SG_ CELL_4x13_Voltage : 0|16@1- (1,0) [0|0] "V" Vector__XXX

BO_ 2147971165 CELL_5x13_MSG: 8 BMS
 SG_ CELL_5x13_isDischarging : 32|1@1- (1,0) [0|0] "V" Vector__XXX
 SG_ CELL_5x13_Temps : 16|16@1- (1,0) [0|0] "V" Vector__XXX
 SG_ CELL_5x13_Voltage : 0|16@1- (1,0) [0|0] "V" Vector__XXX

BO_ 2147971181 CELL_6x13_MSG: 8 BMS
 SG_ CELL_6x13_isDischarging : 32|1@1- (1,0) [0|0] "V" Vector__XXX
 SG_ CELL_6x13_Temps : 16|16@1- (1,0) [0|0] "V" Vector__XXX
 SG_ CELL_6x13_Voltage : 0|16@1- (1,0) [0|0] "V" Vector__XXX

BO_ 2147971086 CELL_0x14_MSG: 8 BMS
 SG_ CELL_0x14_isDischarging : 32|1@1- (1,0) [0|0] "V" Vector__XXX
 SG_ CELL_0x14_Temps : 16|16@1- (1,0) [0|0] "V" Vector__XXX
 SG_ CELL_0x14_Voltage : 0|16@1- (1,0) [0|0] "V" Vector__XXX

BO_ 2147971102 CELL_1x14_MSG: 8 BMS
 SG_ CELL_1x14_isDischarging : 32|1@1- (1,0) [0|0] "V" Vector__XXX
 SG_ CELL_1x14_Temps : 16|16@1- (1,0) [0|0] "V" Vector__XXX
 SG_ CELL_1x14_Voltage : 0|16@1- (1,0) [0|0] "V" Vector__XXX

BO_ 2147971118 CELL_2x14_MSG: 8 BMS
 SG_ CELL_2x14_isDischarging : 32|1@1- (1,0) [0|0] "V" Vector__XXX
 SG_ CELL_2x14_Temps : 16|16@1- (1,0) [0|0] "V" Vector__XXX
 SG_ CELL_2x14_Voltage : 0|16@1- (1,0) [0|0] "V" Vector__XXX

BO_ 2147971134 CELL_3x14_MSG: 8 BMS
 SG_ CELL_3x14_isDischarging : 32|1@1- (1,0) [0|0] "V" Vector__XXX
 SG_ CELL_3x14_Temps : 16|16@1- (1,0) [0|0] "V" Vector__XXX
 SG_ CELL_3x14_Voltage : 0|16@1- (1,0) [0|0] "V" Vector__XXX

BO_ 2147971150 CELL_4x14_MSG: 8 BMS
 SG_ CELL_4x14_isDischarging : 32|1@1- (1,0) [0|0] "V" Vector__XXX
 SG_ CELL_4x14_Temps : 16|16@1- (1,0) [0|0] "V" Vector__XXX
 SG_ CELL_4x14_Voltage : 0|16@1- (1,0) [0|0] "V" Vector__XXX

BO_ 2147971166 CELL_5x14_MSG: 8 BMS
 SG_ CELL_5x14_isDischarging : 32|1@1- (1,0) [0|0] "V" Vector__XXX
 SG_ CELL_5x14_Temps : 16|16@1- (1,0) [0|0] "V" Vector__XXX
 SG_ CELL_5x14_Voltage : 0|16@1- (1,0) [0|0] "V" Vector__XXX

BO_ 2147971182 CELL_6x14_MSG: 8 BMS
 SG_ CELL_6x14_isDischarging : 32|1@1- (1,0) [0|0] "V" Vector__XXX
 SG_ CELL_6x14_Temps : 16|16@1- (1,0) [0|0] "V" Vector__XXX
 SG_ CELL_6x14_Voltage : 0|16@1- (1,0) [0|0] "V" Vector__XXX

BO_ 2147971087 CELL_0x15_MSG: 8 BMS
 SG_ CELL_0x15_isDischarging : 32|1@1- (1,0) [0|0] "V" Vector__XXX
 SG_ CELL_0x15_Temps : 16|16@1- (1,0) [0|0] "V" Vector__XXX
 SG_ CELL_0x15_Voltage : 0|16@1- (1,0) [0|0] "V" Vector__XXX

BO_ 2147971103 CELL_1x15_MSG: 8 BMS
 SG_ CELL_1x15_isDischarging : 32|1@1- (1,0) [0|0] "V" Vector__XXX
 SG_ CELL_1x15_Temps : 16|16@1- (1,0) [0|0] "V" Vector__XXX
 SG_ CELL_1x15_Voltage : 0|16@1- (1,0) [0|0] "V" Vector__XXX

BO_ 2147971119 CELL_2x15_MSG: 8 BMS
 SG_ CELL_2x15_isDischarging : 32|1@1- (1,0) [0|0] "V" Vector__XXX
 SG_ CELL_2x15_Temps : 16|16@1- (1,0) [0|0] "V" Vector__XXX
 SG_ CELL_2x15_Voltage : 0|16@1- (1,0) [0|0] "V" Vector__XXX

BO_ 2147971135 CELL_3x15_MSG: 8 BMS
 SG_ CELL_3x15_isDischarging : 32|1@1- (1,0) [0|0] "V" Vector__XXX
 SG_ CELL_3x15_Temps : 16|16@1- (1,0) [0|0] "V" Vector__XXX
 SG_ CELL_3x15_Voltage : 0|16@1- (1,0) [0|0] "V" Vector__XXX

BO_ 2147971151 CELL_4x15_MSG: 8 BMS
 SG_ CELL_4x15_isDischarging : 32|1@1- (1,0) [0|0] "V" Vector__XXX
 SG_ CELL_4x15_Temps : 16|16@1- (1,0) [0|0] "V" Vector__XXX
 SG_ CELL_4x15_Voltage : 0|16@1- (1,0) [0|0] "V" Vector__XXX

BO_ 2147971167 CELL_5x15_MSG: 8 BMS
 SG_ CELL_5x15_isDischarging : 32|1@1- (1,0) [0|0] "V" Vector__XXX
 SG_ CELL_5x15_Temps : 16|16@1- (1,0) [0|0] "V" Vector__XXX
 SG_ CELL_5x15_Voltage : 0|16@1- (1,0) [0|0] "V" Vector__XXX

BO_ 2147971183 CELL_6x15_MSG: 8 BMS
 SG_ CELL_6x15_isDischarging : 32|1@1- (1,0) [0|0] "V" Vector__XXX
 SG_ CELL_6x15_Temps : 16|16@1- (1,0) [0|0] "V" Vector__XXX
 SG_ CELL_6x15_Voltage : 0|16@1- (1,0) [0|0] "V" Vector__XXX
